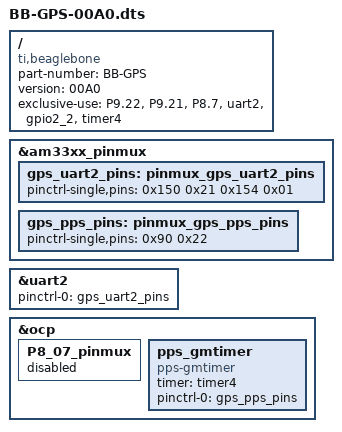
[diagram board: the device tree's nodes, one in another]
/*
 * Copyright (C) 2013 the8thlayerof.net
 *
 * GPS cape
 * UART2 on pins P9.21, P9.22
 * PPS on pin P8.7
 *
 * This program is free software; you can redistribute it and/or modify
 * it under the terms of the GNU General Public License version 2 as
 * published by the Free Software Foundation.
 */
/dts-v1/;
/plugin/;

/ {
   compatible = "ti,beaglebone", "ti,beaglebone-black";

        /* identification */
        part-number = "BB-GPS";
        version = "00A0";

        /* state the resources this cape uses */
        exclusive-use =
                /* the pin header uses */
                "P9.22",        /* uart2_rxd/GPS TX */
                "P9.21",        /* uart4_txd/GPS RX */
                "P8.7",         /* timer4/GPS PPS   */
                /* the hardware ip uses */
                "uart2",   /* 0-based counting */
                "gpio2_2", /* 0-based counting */
		"timer4";  /* 1-based counting */

        fragment@0 {
                target = <&am33xx_pinmux>;
                __overlay__ {
                        gps_uart2_pins: pinmux_gps_uart2_pins {
                                pinctrl-single,pins = <
					0x150 0x21	/* spi0_sclk.uart2_rxd | MODE1 */
					0x154 0x01	/* spi0_d0.uart2_txd | MODE1 */
                               >;
                        };

                        gps_pps_pins: pinmux_gps_pps_pins {
				pinctrl-single,pins = <
				      0x90 0x22 /* P8.7 MODE2 TIMER4 */
				>;
			};

                };
        };

	fragment@1 {
                target = <&uart2>;	/* 1-based counting */
                __overlay__ {
                        status = "okay";
                        pinctrl-names = "default";
                        pinctrl-0 = <&gps_uart2_pins>;
                };
	};

	fragment@2 {
		target = <&ocp>;

                __overlay__ {
			P8_07_pinmux { status = "disabled"; };
			pps_gmtimer {
				compatible = "pps-gmtimer";
				status = "okay";
				timer = <&timer4>;
				pinctrl-names = "default";
				pinctrl-0 = <&gps_pps_pins>;
			};
		};
	};
};
